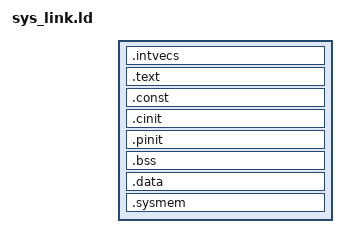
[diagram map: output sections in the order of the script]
/*----------------------------------------------------------------------------*/
/* Memory Map                                                                 */

MEMORY
{
    VECTORS (X)  : origin=0x00000000 length=0x00000020
    FLASH0  (RX) : origin=0x00000020 length=0x0013FFE0
    STACKS  (RW) : origin=0x08000000 length=0x00001500
    RAM     (RW) : origin=0x08001500 length=0x0002EB00

/* USER CODE BEGIN (2) */
/* USER CODE END */
}

/* USER CODE BEGIN (3) */
/* USER CODE END */

/*----------------------------------------------------------------------------*/
/* Section Configuration                                                      */

SECTIONS
{
    .intvecs : {} > VECTORS
    .text    : {} > FLASH0 
    .const   : {} > FLASH0 
    .cinit   : {} > FLASH0 
    .pinit   : {} > FLASH0 
    .bss     : {} > RAM
    .data    : {} > RAM
    .sysmem  : {} > RAM
    KEEP(*(.intvecs))
}
